# STM32MP23_CM33 register map
File version: 1.2
CPU: CM33 r0p1, little endian, MPU, FPU, vendor SysTick, 8 interrupt priority bits
Registers are 32-bit, read-write, reset 0x0 unless marked. A register's access mark holds for its fields unless they carry their own. Offsets are from the block's base; [hi:lo] are bit positions; {n}, {i} and the like mark numbered series.

## RISAB1 — RISAB register block
Base 0x420F0000
Same registers: RISAB2 0x42100000, RISAB3 0x42110000, RISAB4 0x42120000, RISAB5 0x42130000, RISAB6 0x42140000, RISAB1_S 0x520F0000, RISAB2_S 0x52100000, RISAB3_S 0x52110000, RISAB4_S 0x52120000, RISAB5_S 0x52130000, RISAB6_S 0x52140000
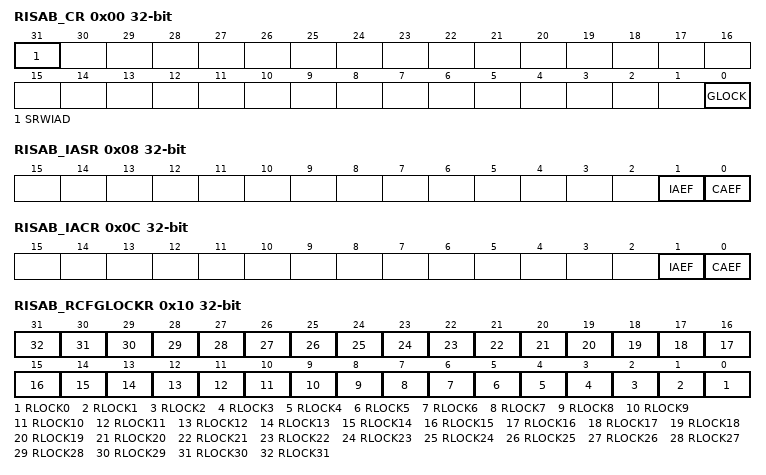
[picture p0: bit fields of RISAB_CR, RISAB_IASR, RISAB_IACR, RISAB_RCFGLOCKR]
0x00 RISAB_CR — RISAB configuration register
  [31] SRWIAD — Secure read/write illegal access disable When set, this bit allows secure read/write data accesses to non-secure blocks and pages (secure execute remains illegal).
    0=Any secure access to non-secure blocks or pages is illegal; 1=Secure read/write data access is allowed to non-secure blocks or pages, while secure execute generates a bus error
  [0] GLOCK — Global lock This bit locks the configuration of RISAB registers until next reset. This bit is cleared by default and, once set, cannot be reset until global RISAB reset.
    0=RISAB registers are writable; 1=All writes to RISAB registers are ignored, except RISAB_IACR
0x08 RISAB_IASR ro — RISAB illegal access status register
  [1] IAEF — Illegal access error flag This bit is set when an illegal access is detected on the system bus. More details on the error can be found in RISAB_IAESR and RISAB_IADDR. This bit is cleared by setting the corresponding bit in RISAB_IACR.
  [0] CAEF — configuration access error flag This bit is set when an illegal access to any RISAB configuration register is detected. This bit is cleared by setting the corresponding bit in RISAB_IACR.
0x0C RISAB_IACR wo — RISAB illegal access clear register
  [1] IAEF — Illegal access error flag Set this bit to clear IAEF in RISAB_IASR, allowing the capture of new error information inRISAB_IAESR and RISAB_IADDR. Note: Clearing this bit does not clear RISAB_IADDR.
  [0] CAEF — Configuration access error flag Set this bit to clear CAEF in RISAB_IASR.
0x10 RISAB_RCFGLOCKR — RISAB configuration lock register
  [all] fields
    0=RISAB_PGy_CIDCFGR, RISAB_PGy_SECCFGR, RISAB_PGy_PRIVCFGR, and RISAB_PGy_C2PRIVCFGR are writable. Bit y in RISAB_CIDxPRIVCFGR, RISAB_CIDxRDCFGR, and RISAB_CIDxWRCFGR are writable (x=0 to 6).; 1=Writes to RISAB_PGy_CIDCFGR, RISAB_PGy_SECCFGR, RISAB_PGy_PRIVCFGR, and RISAB_PGy_C2PRIVCFGR are ignored. Writes to bit y in RISAB_CIDxPRIVCFGR, RISAB_CIDxRDCFGR, and RISAB_CIDxWRCFGR are ignored (m=0 to 6).
  [n] RLOCK{n} (n=0..31) — Resource lock for page y This bit is set to lock page y resource. This bit is cleared by default and, once set, cannot be cleared until RISAB is reset.
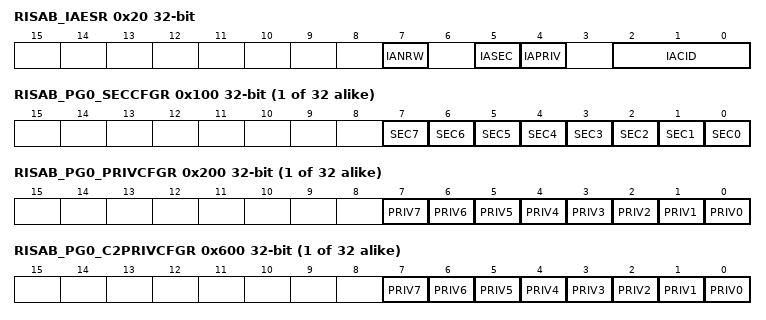
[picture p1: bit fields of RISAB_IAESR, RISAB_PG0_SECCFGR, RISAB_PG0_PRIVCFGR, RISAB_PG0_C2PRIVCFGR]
0x20 RISAB_IAESR ro — RISAB illegal access error status register
  [7] IANRW — Illegal access read/write When IAEF = 1 in RISAB_IASR, IANRW captures the access type of the illegal access that occurred on the system bus.
    0=Illegal access was a data read; 1=Illegal access was a data write
  [5] IASEC — Illegal access security When IAEF = 1 in RISAB_IASR, IASEC captures the security type of the illegal access that occurred on the system bus.
    0=Illegal access was non-secure; 1=Illegal access was secure
  [4] IAPRIV — Illegal access privileged When IAEF = 1 in RISAB_IASR, IAPRIV captures the privilege state of the master that issued the illegal access on the system bus.
    0=Illegal access was unprivileged; 1=Illegal access was privileged
  [2:0] IACID — illegal access compartment ID When IAEF = 1 in RISAB_IASR, IACID[2:0] captures the compartment ID of the master that issued the illegal access on the system bus.
0x24 RISAB_IADDR ro — RISAB illegal address register
  [31:0] IADD — Illegal address When IAEF = 1 in RISAB_IASR, IADD[31:0] captures the address of the erroneous access. Additional information can be found in RISAB_IAESR.
{0x100+4i} RISAB_PG{i}_SECCFGR (reset mask 0xFFFFFF00) (i=0..31) — RISAB page {i} security configuration register
  [all] fields
    0=Only non-secure requests can access block z of page y. Secure data access can be granted if SRWIAD = 1 in RISAB_CR (secure instruction fetch triggers a bus error).; 1=Only secure requests can access block z of page y
  [n] SEC{n} (n=0..7) — Security configuration for block z
{0x200+4i} RISAB_PG{i}_PRIVCFGR (i=0..31) — RISAB page {i} default privileged configuration register
  [all] fields
    0=Privileged and unprivileged access are granted to block z of page y; 1=Only privileged access is granted to block z of page y
  [n] PRIV{n} (n=0..7) — Privileged configuration for block z This bit is ignored if the filtering per compartment is activated for page y (CFEN = 1 in RISAB_PGy_CIDCFGR). Note: Non-secure write to this bit is ignored if SECz is set in RISAB_PGy_SECCFGR.
{0x600+4i} RISAB_PG{i}_C2PRIVCFGR (i=0..31) — RISAB page {i} privileged configuration register for compartment 2
  [all] fields
    0=Compartment 2 privileged and unprivileged accesses are granted to block z of page y, if PRIVy is cleared in RISAB_CID2PRIVCFGR. If PRIVy is set, only privileged access is granted.; 1=Only compartment 2 privileged access is granted to block z of page y
  [n] PRIV{n} (n=0..7) — Privileged configuration for block z This bit is ignored if the filtering per compartment is not activated for page y (CFEN = 0 in RISAB_PGy_CIDCFGR). Note: Non-secure write to this bit is ignored if SECz is set in RISAB_PGy_SECCFGR.
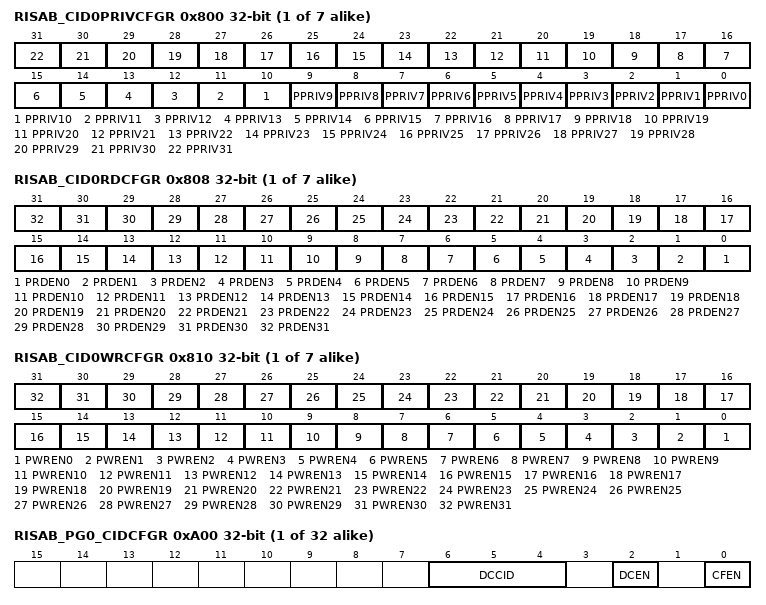
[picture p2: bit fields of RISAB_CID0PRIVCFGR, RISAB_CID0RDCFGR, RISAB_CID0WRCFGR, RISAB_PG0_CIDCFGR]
{0x800+0x20*i} RISAB_CID{i}PRIVCFGR (i=0..6) — RISAB compartment {i} privilege configuration register
  [all] fields
    0=Privileged and unprivileged access for compartment x are granted to page y; 1=Compartment x unprivileged accesses to page y are blocked (read as 0, write is ignored)
  [n] PPRIV{n} (n=0..31) — Page y privileged configuration (y=31 to 0) PPRIVy is ignored if the filtering per compartment is not activated for page y (CFEN = 0 inRISAB_PGy_CIDCFGR). Non-secure write to this bit is ignored if any bit is set in RISAB_PGy_SECCFGR, or if DCEN= 0 while CFEN = 1 in RISAB_PGy_CIDCFGR. Writes are ignored if RLOCKyis set in RISAB_RCFGLOCKR. Note: Additional privilege access control is defined in RISAB_PGy_C2PRIVCFGR. When the delegated configuration is enabled (DCEN = 1 in RISAB_PGy_CIDCFGR), only the compartment DCCID defined in RISAB_PGy_CIDCFGR can write to this bit. When the delegation is disabled (DCEN = 0), only the trusted domain CID can write to this bit. Note: When the compartment filtering is disabled (CFEN = 0 in RISAB_PGy_CIDCFGR), any compartment can program this bit.
{0x808+0x20*i} RISAB_CID{i}RDCFGR (i=0..6) — RISAB compartment {i} read configuration register
  [all] fields
    0=Compartment x read as 0 when accessing page y; 1=Compartment x can read page y
  [n] PRDEN{n} (n=0..31) — Page y read access enable (y=31 to 0) PRDENy is ignored if the filtering per compartment is not activated for page y (CFEN = 0 inRISAB_PGy_CIDCFGR). Non-secure write to this bit field is ignored if any bit is set in RISAB_PGy_SECCFGR, or if DCEN = 0 while CFEN = 1 in RISAB_PGy_CIDCFGR. Writes are ignored if RLOCKyis set in RISAB_RCFGLOCKR. When the delegated configuration is enable (DCEN = 1 in RISAB_PGy_CIDCFGR), only the compartment DCCID defined in RISAB_PGy_CIDCFGR can write to this bit. When the delegation is disabled (DCEN = 0), only the trusted domain CID can write tothis bit. Note: When compartment filtering is disabled (CFEN = 0 in RISAB_PGy_CIDCFGR), any compartment can program this bit.
{0x810+0x20*i} RISAB_CID{i}WRCFGR (i=0..6) — RISAB compartment {i} write configuration register
  [all] fields
    0=Compartment x write to page y is ignored; 1=Compartment x can write page y
  [n] PWREN{n} (n=0..31) — Page y write access enable (y=31 to 0) PWRENy is ignored if the filtering per compartment is not activated for page y (CFEN = 0 in RISAB_PGy_CIDCFGR). Non-secure write to this bit field is ignored if any bit is set in RISAB_PGy_SECCFGR, or if DCEN = 0 while CFEN = 1 in RISAB_PGy_CIDCFGR. Writes are ignored if RLOCKyis set in RISAB_RCFGLOCKR. When the delegated configuration is enable (DCEN = 1 in RISAB_PGy_CIDCFGR), only the compartment DCCID defined in RISAB_PGy_CIDCFGR can write to this bit. When the delegation is disabled (DCEN = 0), only the trusted domain CID can write to this bit. Note: When compartment filtering is disabled (CFEN = 0 in RISAB_PGy_CIDCFGR), any compartment can program this bit.
{0xA00+4i} RISAB_PG{i}_CIDCFGR (i=0..31) — RISAB page {i} CID configuration register
  [6:4] DCCID — Delegated configuration CID The trusted domain application can use this bit field to statically define which compartment can program the security domain of page y, if DCEN = 1.
  [2] DCEN — Delegated configuration enable This bit defines the access control of RISAB_PGy_SECCFGR, PPRIVy inRISAB_CIDxPRIVCFGR, PRDENy in RISAB_CIDxRDCFGR, and PWRENy inRISAB_CIDxWRCFGR. Note: When DCEN is set, the configuration application must be secure if at least one bit is set inRISAB_PGy_SECCFGR.
    0=Bit/register can be written only by trusted domain application; 1=Bit/register can be written only by the compartment DCCID[2:0], defined in this register
  [0] CFEN — CID filtering enable Note: For any CFEN value, the access controls to page y, defined in RISAB_PGy_SECCFGR, and RISAB_zzPRIVCFGR (zz = PGy_ if CFEN = 0, zz=PGy_C2 or CIDx if CFEN = 1) always apply.
    0=Compartment-based filtering is disabled for page y; 1=Compartment-based filtering is enabled for page y
0xFE8 RISAB_HWCFGR3 ro — RISAB hardware configuration register 3
  [31:0] CFG — Hardware configuration This bit field returns 0x0.
0xFEC RISAB_HWCFGR2 ro reset 0x20000 — RISAB hardware configuration register 2
  [31:0] CFG — Hardware configuration This bit field returns the protected memory size in bytes.
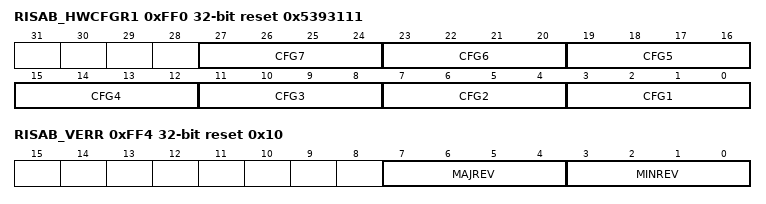
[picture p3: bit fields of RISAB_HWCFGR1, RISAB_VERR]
0xFF0 RISAB_HWCFGR1 ro reset 0x5393111 — RISAB hardware configuration register 1
  [27:24] CFG7 — Hardware configuration 7 This bit field returns the number of pages (LOG_NUM_PAGE).
  [23:20] CFG6 — Hardware configuration 6 This bit field returns the number of blocks per pages (LOG_BLOCKS_PER_PAGE).
  [19:16] CFG5 — Hardware configuration 5 This bit field returns the block size (LOG_BLOCK_SIZE).
  [15:12] CFG4 — Hardware configuration 4 This bit field returns the generic value CID_WIDTH.
  [11:8] CFG3 — Hardware configuration 3 This bit field returns the generic value PRIV_ENABLED.
  [7:4] CFG2 — Hardware configuration 2 This bit field returns the generic value SEC_ENABLED.
  [3:0] CFG1 — Hardware configuration 1 This bit field returns the generic value RIF_ENABLED.
0xFF4 RISAB_VERR ro reset 0x10 — RISAB version register
  [7:4] MAJREV — RISAB major revision
  [3:0] MINREV — RISAB minor revision
0xFF8 RISAB_IPIDR ro reset 0x100160 (reset mask 0xFFFFFFF0) — RISAB identification register
  [31:0] ID — RISAB identification code
0xFFC RISAB_SIDR ro reset 0xA3C5DD04 — RISAB size identification register
  [31:0] SID — RISAB size identification code Bits[31:8] = 0xA3C5DD (fixed code) Bits[7:0] = 0x04 (4-Kbyte address decoding)
